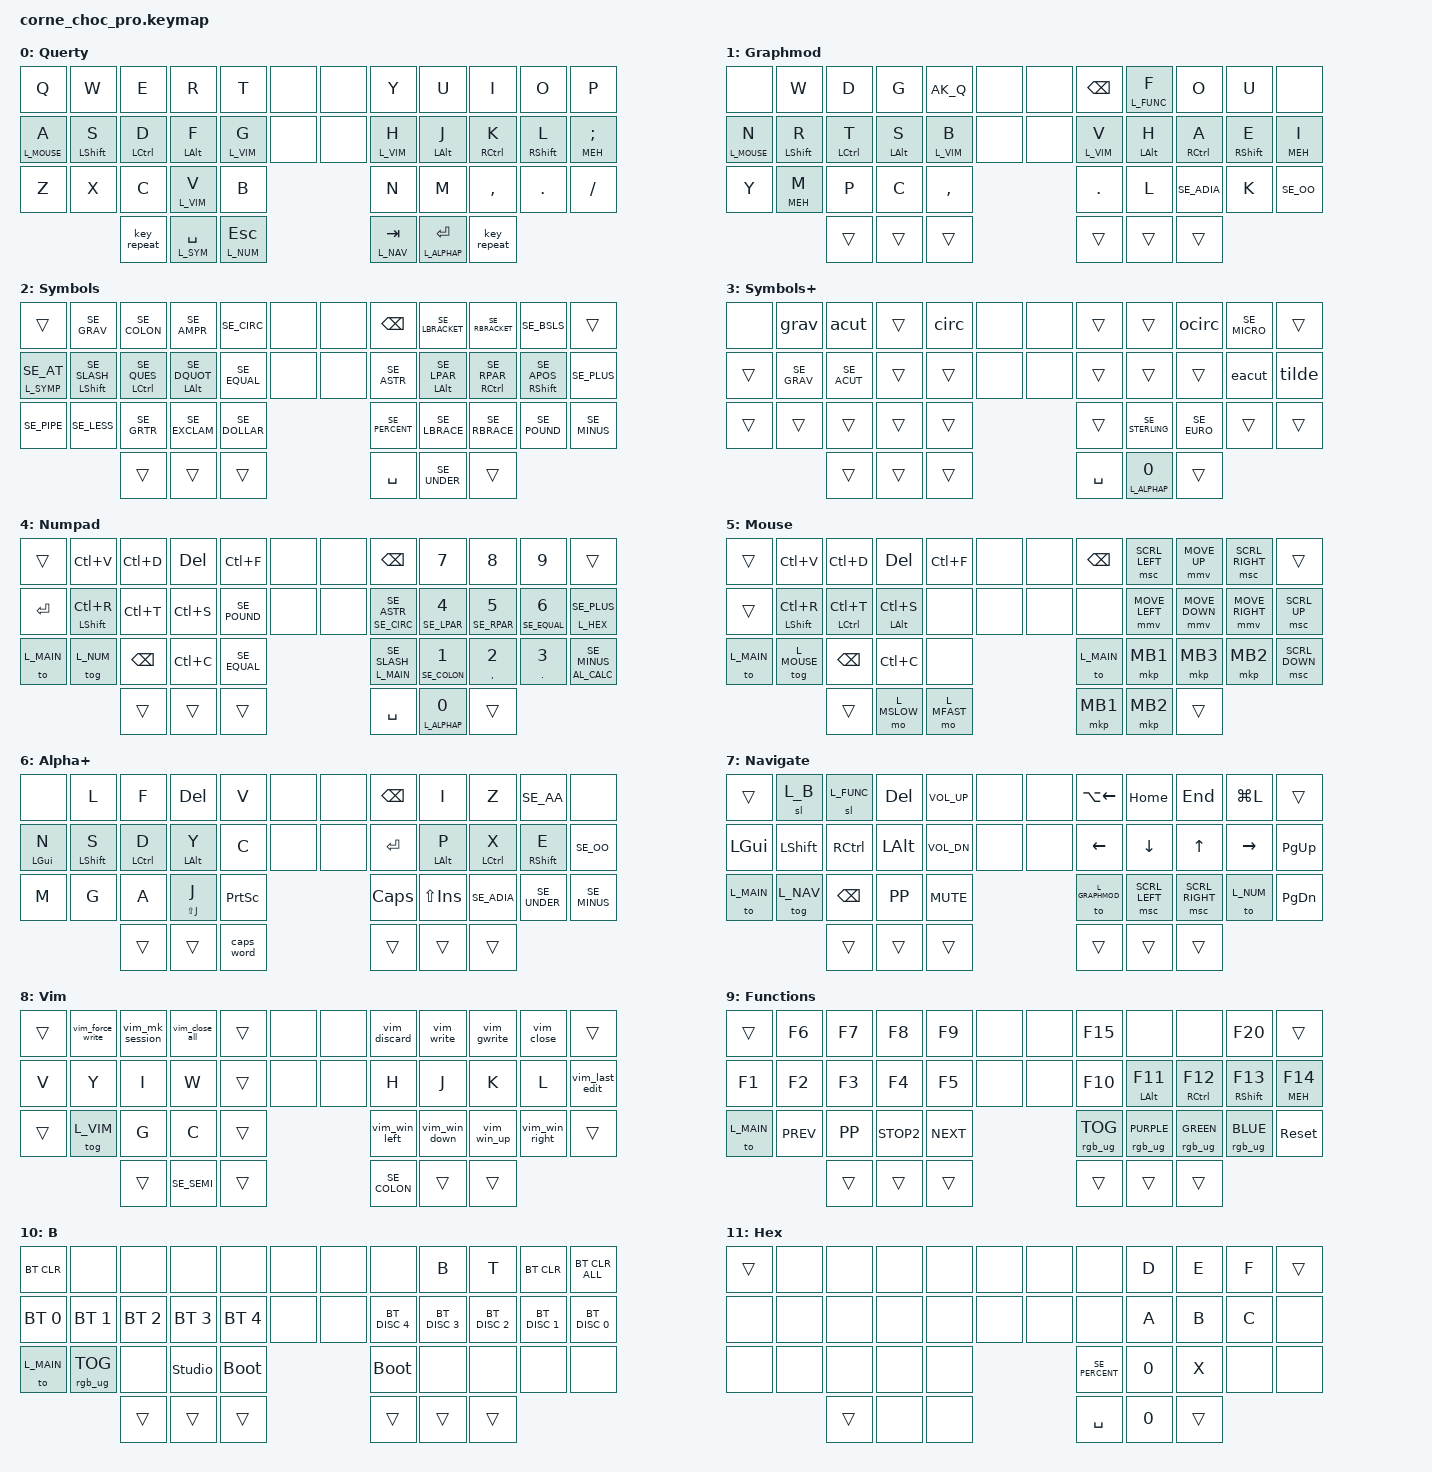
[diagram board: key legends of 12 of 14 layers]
/*
 * Copyright (c) 2020 The ZMK Contributors
 *
 * SPDX-License-Identifier: MIT
 */

#include <behaviors.dtsi>
#include <dt-bindings/zmk/keys.h>
#include <dt-bindings/zmk/bt.h>
#include <dt-bindings/zmk/rgb.h>
#include <dt-bindings/zmk/pointing.h>
#include <input/processors.dtsi>

#define SE_CIRC LS(RIGHT_BRACKET)
#define SE_DOLLAR RA(N4)
#define SE_COLON LS(DOT)
#define SE_SEMI LS(COMMA)
#define SE_AMPR LS(N6)
#define SE_ACUT EQUAL
#define SE_AT RA(N2)
#define SE_SLASH LS(N7)
#define SE_QUES LS(MINUS)
#define SE_DQUOT LS(N2)
#define SE_APOS NUHS
#define SE_LESS NUBS
#define SE_MINUS FSLH
#define SE_UNDER LS(FSLH)
#define SE_EQUAL LS(N0)
#define SE_GRTR LS(NUBS)
#define SE_LBRACE RA(N7)
#define SE_RBRACE RA(N0)
#define SE_BSLS RA(MINUS)
#define SE_TILDE RA(RIGHT_BRACKET)
#define SE_LPAR LS(N8)
#define SE_RPAR LS(N9)
#define SE_PLUS MINUS
#define SE_ASTR LS(NUHS)
#define SE_GRAV LS(EQUAL)
#define SE_LBRACKET RA(N8)
#define SE_RBRACKET RA(N9)
#define SE_PIPE RA(NUBS)
#define SE_SECT GRAV
#define SE_PERCENT LS(N5)
#define SE_EXCLAM LS(N1)
#define SE_POUND LS(N3)
#define SE_MICRO RA(M)
#define SE_EURO RA(N5)
#define SE_STERLING RA(N3)
#define SE_ADIA APOS
#define SE_AA LEFT_BRACKET
#define SE_OO SEMI

#define L_QWERTY 0
#define L_GRAPHMOD 1
#define L_SYM 2
#define L_SYMP 3
#define L_NUM 4
#define L_MOUSE 5
#define L_ALPHAP 6
#define L_NAV 7
#define L_VIM 8
#define L_FUNC 9
#define L_B 10
#define L_HEX 11
// Speed modifiers for the Mouse layer: all-&trans layers that exist only so the
// pointer/scroll input listeners can scale their events while one is held.
#define L_MFAST 12
#define L_MSLOW 13
#define L_MAIN L_QWERTY

// MEH = Ctrl + Shift + Alt
#define MEH LC(LS(LALT))

// Shortcuts for workspaces
#define WS_L LC(LA(LEFT))
#define WS_R LC(LA(RIGHT))
#define WSM_L LS(LA(LEFT))
#define WSM_R LS(LA(RIGHT))

// Colors
#define GREEN RGB_COLOR_HSB(128,100,100)
#define BLUE RGB_COLOR_HSB(225,85,95)
#define PURPLE RGB_COLOR_HSB(255,80,100)

/ {
    chosen {
        zmk,physical-layout = &five_col_layout;
    };
};

/ {
    behaviors {
        HML: HML {
            compatible = "zmk,behavior-hold-tap";
            bindings = <&kp>, <&kp>;

            #binding-cells = <2>;
            tapping-term-ms = <250>;
            quick-tap-ms = <175>;
            flavor = "balanced";
            hold-trigger-on-release;
            require-prior-idle-ms = <100>;
            hold-trigger-key-positions = <7 8 9 10 11 19 20 21 22 23 29 30 31 32 33>;
        };

        HMR: HMR {
            compatible = "zmk,behavior-hold-tap";
            bindings = <&kp>, <&kp>;

            #binding-cells = <2>;
            tapping-term-ms = <250>;
            quick-tap-ms = <175>;
            flavor = "balanced";
            hold-trigger-on-release;
            require-prior-idle-ms = <100>;
            hold-trigger-key-positions = <0 1 2 3 4 12 13 14 15 16 24 25 26 27 28>;
        };

        HT_TO: HT_TO {
            compatible = "zmk,behavior-hold-tap";
            bindings = <&to>, <&kp>;

            #binding-cells = <2>;
            tapping-term-ms = <250>;
            flavor = "tap-preferred";
        };

        NUM: NUM {
            compatible = "zmk,behavior-hold-tap";
            bindings = <&kp>, <&kp>;

            #binding-cells = <2>;
            tapping-term-ms = <200>;
            quick-tap-ms = <175>;
            require-prior-idle-ms = <100>;
            flavor = "tap-preferred";
        };

        LT_TH: LT_TH {
            compatible = "zmk,behavior-hold-tap";
            bindings = <&mo>, <&kp>;

            #binding-cells = <2>;
            tapping-term-ms = <200>;
            quick-tap-ms = <150>;
            require-prior-idle-ms = <100>;
            flavor = "tap-preferred";
        };

        // Adaptive Q: N -> Q sends J, otherwise plain Q.
        AK_Q: AK_Q {
            compatible = "zmk,behavior-adaptive-key";
            #binding-cells = <0>;
            bindings = <&kp Q>;

            ak_nq { trigger-keys = <N>; max-prior-idle-ms = <300>; bindings = <&kp J>; };
        };
    };
};

        //                               Key positions
        //
        //╭────┬────┬────┬────┬────╮                      ╭────┬────┬────┬────┬────╮
        //   0    1    2    3    4          5     6          7    8    9   10   11
        //├────┼────┼────┼────┼────┤                      ├────┼────┼────┼────┼────┤
        //  12   13   14   15   16         17    18         19   20   21   22   23
        //├────┼────┼────┼────┼────┤                      ├────┼────┼────┼────┼────┤
        //  24   25   26   27   28                          29   30   31   32   33
        //╰────┴────┼────┼────┼────┤                      ├────┼────┼────┼────┴────╯
        //            34   35   36                          37   38   39
        //          ╰────┴────┴────╯                      ╰────┴────┴────╯
        //
        // The layers are a port of the Kibård keymap (5x3 + 2 thumbs per half):
        // 5, 6, 17 and 18 are unused, and the outer thumbs 34/39 are repeat.


// Mouse speed control. `&mmv`/`&msc` feed their events through these listeners,
// so scaling them here changes pointer/scroll speed without touching a single
// binding: on the Mouse layer hold pos 36 (left inner thumb) for L_MFAST or
// pos 35 (left middle thumb) for L_MSLOW while the right hand drives the mouse.
// Both are `&trans` layers, so the Mouse layer keeps working underneath.
//
// The parameters are <multiplier divisor>, max 16 each. Tune here only.
&mmv_input_listener {
    fast { layers = <L_MFAST>; input-processors = <&zip_xy_scaler 3 1>; };
    slow { layers = <L_MSLOW>; input-processors = <&zip_xy_scaler 1 4>; };
};

&msc_input_listener {
    fast { layers = <L_MFAST>; input-processors = <&zip_scroll_scaler 2 1>; };
    slow { layers = <L_MSLOW>; input-processors = <&zip_scroll_scaler 1 3>; };
};

// Functions is a sticky layer (&sl from Navigate): it stays on until the next
// key press, or until this timeout passes with nothing pressed.
&sl {
    release-after-ms = <5000>;
};

/ {
    macros {
        vim_write: vim_write {
            compatible = "zmk,behavior-macro";
            #binding-cells = <0>;
            bindings
                = <&macro_press &kp LSHFT>
                , <&macro_tap &kp DOT>
                , <&macro_release &kp LSHFT>
                , <&macro_tap &kp W>
                , <&macro_tap &kp RET>
                ;
        };

        vim_close: vim_close {
            compatible = "zmk,behavior-macro";
            #binding-cells = <0>;
            bindings
                = <&macro_press &kp LSHFT>
                , <&macro_tap &kp DOT>
                , <&macro_release &kp LSHFT>
                , <&macro_tap &kp Q>
                , <&macro_tap &kp RET>
                ;
        };

        vim_close_all: vim_close_all {
            compatible = "zmk,behavior-macro";
            #binding-cells = <0>;
            bindings
                = <&macro_press &kp LSHFT>
                , <&macro_tap &kp DOT>
                , <&macro_release &kp LSHFT>
                , <&macro_tap &kp Q &kp A>
                , <&macro_tap &kp RET>
                ;
        };

        vim_mk_session: vim_mk_session {
            compatible = "zmk,behavior-macro";
            #binding-cells = <0>;
            bindings
                = <&macro_press &kp LSHFT>
                , <&macro_tap &kp DOT>
                , <&macro_release &kp LSHFT>
                , <&macro_tap &kp M &kp K &kp S &kp E &kp S &kp S &kp I &kp O &kp N>
                , <&macro_press &kp LSHFT>
                , <&macro_tap &kp N1>
                , <&macro_release &kp LSHFT>
                , <&macro_tap &kp RET>
                ;
        };

        vim_gwrite: vim_gwrite {
            compatible = "zmk,behavior-macro";
            #binding-cells = <0>;
            bindings
                = <&macro_press &kp LSHFT>
                , <&macro_tap &kp DOT>
                , <&macro_tap &kp G>
                , <&macro_release &kp LSHFT>
                , <&macro_tap &kp W &kp R &kp I &kp T &kp E>
                , <&macro_tap &kp RET>
                ;
        };

        vim_discard: vim_discard {
            compatible = "zmk,behavior-macro";
            #binding-cells = <0>;
            bindings
                = <&macro_press &kp LSHFT>
                , <&macro_tap &kp DOT>
                , <&macro_release &kp LSHFT>
                , <&macro_tap &kp Q>
                , <&macro_tap &kp SE_EXCLAM>
                , <&macro_tap &kp RET>
                ;
        };

        vim_force_write: vim_force_write {
            compatible = "zmk,behavior-macro";
            #binding-cells = <0>;
            bindings
                = <&macro_press &kp LSHFT>
                , <&macro_tap &kp DOT>
                , <&macro_release &kp LSHFT>
                , <&macro_tap &kp W>
                , <&macro_tap &kp SE_EXCLAM>
                , <&macro_tap &kp RET>
                ;
        };

        vim_win_left: vim_win_left {
            compatible = "zmk,behavior-macro";
            #binding-cells = <0>;
            bindings
                = <&macro_press &kp LCTRL>
                , <&macro_tap &kp W>
                , <&macro_release &kp LCTRL>
                , <&macro_tap &kp H>
                ;
        };

        vim_win_down: vim_win_down {
            compatible = "zmk,behavior-macro";
            #binding-cells = <0>;
            bindings
                = <&macro_press &kp LCTRL>
                , <&macro_tap &kp W>
                , <&macro_release &kp LCTRL>
                , <&macro_tap &kp J>
                ;
        };

        vim_win_up: vim_win_up {
            compatible = "zmk,behavior-macro";
            #binding-cells = <0>;
            bindings
                = <&macro_press &kp LCTRL>
                , <&macro_tap &kp W>
                , <&macro_release &kp LCTRL>
                , <&macro_tap &kp K>
                ;
        };

        vim_win_right: vim_win_right {
            compatible = "zmk,behavior-macro";
            #binding-cells = <0>;
            bindings
                = <&macro_press &kp LCTRL>
                , <&macro_tap &kp W>
                , <&macro_release &kp LCTRL>
                , <&macro_tap &kp L>
                ;
        };

        vim_last_edit: vim_last_edit {
            compatible = "zmk,behavior-macro";
            #binding-cells = <0>;
            bindings
                = <&macro_tap &kp G>
                , <&macro_press &kp LSHIFT>
                , <&macro_tap &kp COMMA>
                , <&macro_release &kp LSHIFT>
                ;
        };

        acut: acut {
            compatible = "zmk,behavior-macro";
            #binding-cells = <0>;
            bindings
                = <&macro_tap &kp SE_ACUT>
                , <&macro_tap &kp SE_ACUT>
                ;
        };

        grav: grav {
            compatible = "zmk,behavior-macro";
            #binding-cells = <0>;
            bindings
                = <&macro_tap &kp SE_GRAV>
                , <&macro_tap &kp SPACE>
                ;
        };

        tilde: tilde {
            compatible = "zmk,behavior-macro";
            #binding-cells = <0>;
            bindings
                = <&macro_tap &kp SE_TILDE>
                , <&macro_tap &kp SPACE>
                ;
        };

        circ: circ {
            compatible = "zmk,behavior-macro";
            #binding-cells = <0>;
            bindings
                = <&macro_tap &kp SE_CIRC>
                , <&macro_tap &kp SPACE>
                ;
        };

        eacut: eacut {
            compatible = "zmk,behavior-macro";
            #binding-cells = <0>;
            bindings
                = <&macro_tap &kp SE_ACUT>
                , <&macro_tap &kp E>
                ;
        };

        ocirc: ocirc {
            compatible = "zmk,behavior-macro";
            #binding-cells = <0>;
            bindings
                = <&macro_tap &kp SE_CIRC>
                , <&macro_tap &kp O>
                ;
        };
    };
};

/ {
    combos {
        compatible = "zmk,combos";

        combo_esc {
            timeout-ms = <40>;
            key-positions = <1 2>;
            bindings = <&kp ESC>;
        };
    };
};

/ {
    keymap {
        compatible = "zmk,keymap";

        default_layer {
            display-name = "Querty";
            bindings = <
                //╭─────────────────┬─────────────────┬─────────────────┬─────────────────┬─────────────────╮                      ╭─────────────────┬─────────────────┬─────────────────┬─────────────────┬─────────────────╮
                    &kp Q             &kp W             &kp E             &kp R             &kp T                 &none  &none       &kp Y             &kp U             &kp I             &kp O             &kp P
                //├─────────────────┼─────────────────┼─────────────────┼─────────────────┼─────────────────┤                      ├─────────────────┼─────────────────┼─────────────────┼─────────────────┼─────────────────┤
                    &LT_TH L_MOUSE A  &HML LSHIFT S     &HML LCTRL D      &HML LALT F       &lt L_VIM G           &none  &none       &lt L_VIM H       &HMR LALT J       &HMR RCTRL K      &HMR RSHIFT L     &HMR MEH SEMI
                //├─────────────────┼─────────────────┼─────────────────┼─────────────────┼─────────────────┤                      ├─────────────────┼─────────────────┼─────────────────┼─────────────────┼─────────────────┤
                    &kp Z             &kp X             &kp C             &lt L_VIM V       &kp B                                    &kp N             &kp M             &kp COMMA         &kp DOT           &kp FSLH
                //╰─────────────────┴─────────────────┼─────────────────┼─────────────────┼─────────────────┤                      ├─────────────────┼─────────────────┼─────────────────┼─────────────────┴─────────────────╯
                                                        &key_repeat       &LT_TH L_SYM SPACE  &LT_TH L_NUM ESC                       &LT_TH L_NAV TAB  &LT_TH L_ALPHAP RET  &key_repeat
                //                                    ╰─────────────────┴─────────────────┴─────────────────╯                      ╰─────────────────┴─────────────────┴─────────────────╯
            >;
        };

        graphmod_layer {
            display-name = "Graphmod";
            bindings = <
                //╭─────────────────┬─────────────────┬─────────────────┬─────────────────┬─────────────────╮                      ╭─────────────────┬─────────────────┬─────────────────┬─────────────────┬─────────────────╮
                    &none             &kp W             &kp D             &kp G             &AK_Q                 &none  &none       &kp BSPC          &lt L_FUNC F      &kp O             &kp U             &none
                //├─────────────────┼─────────────────┼─────────────────┼─────────────────┼─────────────────┤                      ├─────────────────┼─────────────────┼─────────────────┼─────────────────┼─────────────────┤
                    &LT_TH L_MOUSE N  &HML LSHIFT R     &HML LCTRL T      &HML LALT S       &lt L_VIM B           &none  &none       &lt L_VIM V       &HMR LALT H       &HMR RCTRL A      &HMR RSHIFT E     &HMR MEH I
                //├─────────────────┼─────────────────┼─────────────────┼─────────────────┼─────────────────┤                      ├─────────────────┼─────────────────┼─────────────────┼─────────────────┼─────────────────┤
                    &kp Y             &HML MEH M        &kp P             &kp C             &kp COMMA                                &kp DOT           &kp L             &kp SE_ADIA       &kp K             &kp SE_OO
                //╰─────────────────┴─────────────────┼─────────────────┼─────────────────┼─────────────────┤                      ├─────────────────┼─────────────────┼─────────────────┼─────────────────┴─────────────────╯
                                                        &trans            &trans            &trans                                   &trans            &trans            &trans
                //                                    ╰─────────────────┴─────────────────┴─────────────────╯                      ╰─────────────────┴─────────────────┴─────────────────╯
            >;
        };

        symbol_layer {
            display-name = "Symbols";
            bindings = <
                //╭─────────────────┬─────────────────┬─────────────────┬─────────────────┬─────────────────╮                      ╭─────────────────┬─────────────────┬─────────────────┬─────────────────┬─────────────────╮
                    &trans            &kp SE_GRAV       &kp SE_COLON      &kp SE_AMPR       &kp SE_CIRC           &none  &none       &kp BSPC          &kp SE_LBRACKET   &kp SE_RBRACKET   &kp SE_BSLS       &trans
                //├─────────────────┼─────────────────┼─────────────────┼─────────────────┼─────────────────┤                      ├─────────────────┼─────────────────┼─────────────────┼─────────────────┼─────────────────┤
                    &LT_TH L_SYMP SE_AT  &HML LSHIFT SE_SLASH  &HML LCTRL SE_QUES  &HML LALT SE_DQUOT  &kp SE_EQUAL  &none  &none    &kp SE_ASTR       &HMR LALT SE_LPAR  &HMR RCTRL SE_RPAR  &HMR RSHIFT SE_APOS  &kp SE_PLUS
                //├─────────────────┼─────────────────┼─────────────────┼─────────────────┼─────────────────┤                      ├─────────────────┼─────────────────┼─────────────────┼─────────────────┼─────────────────┤
                    &kp SE_PIPE       &kp SE_LESS       &kp SE_GRTR       &kp SE_EXCLAM     &kp SE_DOLLAR                            &kp SE_PERCENT    &kp SE_LBRACE     &kp SE_RBRACE     &kp SE_POUND      &kp SE_MINUS
                //╰─────────────────┴─────────────────┼─────────────────┼─────────────────┼─────────────────┤                      ├─────────────────┼─────────────────┼─────────────────┼─────────────────┴─────────────────╯
                                                        &trans            &trans            &trans                                   &kp SPACE         &kp SE_UNDER      &trans
                //                                    ╰─────────────────┴─────────────────┴─────────────────╯                      ╰─────────────────┴─────────────────┴─────────────────╯
            >;
        };

        symbolplus_layer {
            display-name = "Symbols+";
            bindings = <
                //╭─────────────────┬─────────────────┬─────────────────┬─────────────────┬─────────────────╮                      ╭─────────────────┬─────────────────┬─────────────────┬─────────────────┬─────────────────╮
                    &none             &grav             &acut             &trans            &circ                 &none  &none       &trans            &trans            &ocirc            &kp SE_MICRO      &trans
                //├─────────────────┼─────────────────┼─────────────────┼─────────────────┼─────────────────┤                      ├─────────────────┼─────────────────┼─────────────────┼─────────────────┼─────────────────┤
                    &trans            &kp SE_GRAV       &kp SE_ACUT       &trans            &trans                &none  &none       &trans            &trans            &trans            &eacut            &tilde
                //├─────────────────┼─────────────────┼─────────────────┼─────────────────┼─────────────────┤                      ├─────────────────┼─────────────────┼─────────────────┼─────────────────┼─────────────────┤
                    &trans            &trans            &trans            &trans            &trans                                   &trans            &kp SE_STERLING   &kp SE_EURO       &trans            &trans
                //╰─────────────────┴─────────────────┼─────────────────┼─────────────────┼─────────────────┤                      ├─────────────────┼─────────────────┼─────────────────┼─────────────────┴─────────────────╯
                                                        &trans            &trans            &trans                                   &kp SPACE         &lt L_ALPHAP N0   &trans
                //                                    ╰─────────────────┴─────────────────┴─────────────────╯                      ╰─────────────────┴─────────────────┴─────────────────╯
            >;
        };

        numpad_layer {
            display-name = "Numpad";
            bindings = <
                //╭─────────────────┬─────────────────┬─────────────────┬─────────────────┬─────────────────╮                      ╭─────────────────┬─────────────────┬─────────────────┬─────────────────┬─────────────────╮
                    &trans            &kp LC(V)         &kp LC(D)         &kp DEL           &kp LC(F)             &none  &none       &kp BSPC          &kp N7            &kp N8            &kp N9            &trans
                //├─────────────────┼─────────────────┼─────────────────┼─────────────────┼─────────────────┤                      ├─────────────────┼─────────────────┼─────────────────┼─────────────────┼─────────────────┤
                    &kp RET           &HML LSHIFT LC(R)  &kp LC(T)        &kp LC(S)         &kp SE_POUND          &none  &none       &NUM SE_CIRC SE_ASTR  &NUM SE_LPAR N4  &NUM SE_RPAR N5  &NUM SE_EQUAL N6  &LT_TH L_HEX SE_PLUS
                //├─────────────────┼─────────────────┼─────────────────┼─────────────────┼─────────────────┤                      ├─────────────────┼─────────────────┼─────────────────┼─────────────────┼─────────────────┤
                    &to L_MAIN        &tog L_NUM        &kp BSPC          &kp LC(C)         &kp SE_EQUAL                             &HT_TO L_MAIN SE_SLASH  &NUM SE_COLON N1  &NUM COMMA N2  &NUM DOT N3    &NUM C_AL_CALC SE_MINUS
                //╰─────────────────┴─────────────────┼─────────────────┼─────────────────┼─────────────────┤                      ├─────────────────┼─────────────────┼─────────────────┼─────────────────┴─────────────────╯
                                                        &trans            &trans            &trans                                   &kp SPACE         &lt L_ALPHAP N0   &trans
                //                                    ╰─────────────────┴─────────────────┴─────────────────╯                      ╰─────────────────┴─────────────────┴─────────────────╯
            >;
        };

        mouse_layer {
            display-name = "Mouse";
            bindings = <
                //╭─────────────────┬─────────────────┬─────────────────┬─────────────────┬─────────────────╮                      ╭─────────────────┬─────────────────┬─────────────────┬─────────────────┬─────────────────╮
                    &trans            &kp LC(V)         &kp LC(D)         &kp DEL           &kp LC(F)             &none  &none       &kp BSPC          &msc SCRL_LEFT    &mmv MOVE_UP      &msc SCRL_RIGHT   &trans
                //├─────────────────┼─────────────────┼─────────────────┼─────────────────┼─────────────────┤                      ├─────────────────┼─────────────────┼─────────────────┼─────────────────┼─────────────────┤
                    &trans            &HML LSHIFT LC(R)  &HML LCTRL LC(T)  &HML LALT LC(S)  &none                 &none  &none       &none             &mmv MOVE_LEFT    &mmv MOVE_DOWN    &mmv MOVE_RIGHT   &msc SCRL_UP
                //├─────────────────┼─────────────────┼─────────────────┼─────────────────┼─────────────────┤                      ├─────────────────┼─────────────────┼─────────────────┼─────────────────┼─────────────────┤
                    &to L_MAIN        &tog L_MOUSE      &kp BSPC          &kp LC(C)         &none                                    &to L_MAIN        &mkp MB1          &mkp MB3          &mkp MB2          &msc SCRL_DOWN
                //╰─────────────────┴─────────────────┼─────────────────┼─────────────────┼─────────────────┤                      ├─────────────────┼─────────────────┼─────────────────┼─────────────────┴─────────────────╯
                                                        &trans            &mo L_MSLOW       &mo L_MFAST                              &mkp MB1          &mkp MB2          &trans
                //                                    ╰─────────────────┴─────────────────┴─────────────────╯                      ╰─────────────────┴─────────────────┴─────────────────╯
            >;
        };

        alphaplus_layer {
            display-name = "Alpha+";
            bindings = <
                //╭─────────────────┬─────────────────┬─────────────────┬─────────────────┬─────────────────╮                      ╭─────────────────┬─────────────────┬─────────────────┬─────────────────┬─────────────────╮
                    &none             &kp L             &kp F             &kp DEL           &kp V                 &none  &none       &kp BSPC          &kp I             &kp Z             &kp SE_AA         &none
                //├─────────────────┼─────────────────┼─────────────────┼─────────────────┼─────────────────┤                      ├─────────────────┼─────────────────┼─────────────────┼─────────────────┼─────────────────┤
                    &HML LGUI N       &HML LSHIFT S     &HML LCTRL D      &HML LALT Y       &kp C                 &none  &none       &kp RET           &HMR LALT P       &HMR LCTRL X      &HMR RSHIFT E     &kp SE_OO
                //├─────────────────┼─────────────────┼─────────────────┼─────────────────┼─────────────────┤                      ├─────────────────┼─────────────────┼─────────────────┼─────────────────┼─────────────────┤
                    &kp M             &kp G             &kp A             &HML LS(J) J      &kp PSCRN                                &kp CAPS          &kp LS(INS)       &kp SE_ADIA       &kp SE_UNDER      &kp SE_MINUS
                //╰─────────────────┴─────────────────┼─────────────────┼─────────────────┼─────────────────┤                      ├─────────────────┼─────────────────┼─────────────────┼─────────────────┴─────────────────╯
                                                        &trans            &trans            &caps_word                               &trans            &trans            &trans
                //                                    ╰─────────────────┴─────────────────┴─────────────────╯                      ╰─────────────────┴─────────────────┴─────────────────╯
            >;
        };

        navigate_layer {
            display-name = "Navigate";
            bindings = <
                //╭─────────────────┬─────────────────┬─────────────────┬─────────────────┬─────────────────╮                      ╭─────────────────┬─────────────────┬─────────────────┬─────────────────┬─────────────────╮
                    &trans            &sl L_B           &sl L_FUNC        &kp DEL           &kp K_VOL_UP          &none  &none       &kp LA(LEFT)      &kp HOME          &kp END           &kp LG(L)         &trans
                //├─────────────────┼─────────────────┼─────────────────┼─────────────────┼─────────────────┤                      ├─────────────────┼─────────────────┼─────────────────┼─────────────────┼─────────────────┤
                    &kp LGUI          &kp LSHIFT        &kp RCTRL         &kp LALT          &kp K_VOL_DN          &none  &none       &kp LEFT          &kp DOWN          &kp UP            &kp RIGHT         &kp PG_UP
                //├─────────────────┼─────────────────┼─────────────────┼─────────────────┼─────────────────┤                      ├─────────────────┼─────────────────┼─────────────────┼─────────────────┼─────────────────┤
                    &to L_MAIN        &tog L_NAV        &kp BSPC          &kp K_PP          &kp K_MUTE                               &to L_GRAPHMOD    &msc SCRL_LEFT    &msc SCRL_RIGHT   &to L_NUM         &kp PG_DN
                //╰─────────────────┴─────────────────┼─────────────────┼─────────────────┼─────────────────┤                      ├─────────────────┼─────────────────┼─────────────────┼─────────────────┴─────────────────╯
                                                        &trans            &trans            &trans                                   &trans            &trans            &trans
                //                                    ╰─────────────────┴─────────────────┴─────────────────╯                      ╰─────────────────┴─────────────────┴─────────────────╯
            >;
        };

        vim_layer {
            display-name = "Vim";
            bindings = <
                //╭─────────────────┬─────────────────┬─────────────────┬─────────────────┬─────────────────╮                      ╭─────────────────┬─────────────────┬─────────────────┬─────────────────┬─────────────────╮
                    &trans            &vim_force_write  &vim_mk_session   &vim_close_all    &trans                &none  &none       &vim_discard      &vim_write        &vim_gwrite       &vim_close        &trans
                //├─────────────────┼─────────────────┼─────────────────┼─────────────────┼─────────────────┤                      ├─────────────────┼─────────────────┼─────────────────┼─────────────────┼─────────────────┤
                    &kp V             &kp Y             &kp I             &kp W             &trans                &none  &none       &kp H             &kp J             &kp K             &kp L             &vim_last_edit
                //├─────────────────┼─────────────────┼─────────────────┼─────────────────┼─────────────────┤                      ├─────────────────┼─────────────────┼─────────────────┼─────────────────┼─────────────────┤
                    &trans            &tog L_VIM        &kp G             &kp C             &trans                                   &vim_win_left     &vim_win_down     &vim_win_up       &vim_win_right    &trans
                //╰─────────────────┴─────────────────┼─────────────────┼─────────────────┼─────────────────┤                      ├─────────────────┼─────────────────┼─────────────────┼─────────────────┴─────────────────╯
                                                        &trans            &kp SE_SEMI       &trans                                   &kp SE_COLON      &trans            &trans
                //                                    ╰─────────────────┴─────────────────┴─────────────────╯                      ╰─────────────────┴─────────────────┴─────────────────╯
            >;
        };

        functions_layer {
            display-name = "Functions";
            bindings = <
                //╭─────────────────┬─────────────────┬─────────────────┬─────────────────┬─────────────────╮                      ╭─────────────────┬─────────────────┬─────────────────┬─────────────────┬─────────────────╮
                    &trans            &kp F6            &kp F7            &kp F8            &kp F9                &none  &none       &kp F15           &none             &none             &kp F20           &trans
                //├─────────────────┼─────────────────┼─────────────────┼─────────────────┼─────────────────┤                      ├─────────────────┼─────────────────┼─────────────────┼─────────────────┼─────────────────┤
                    &kp F1            &kp F2            &kp F3            &kp F4            &kp F5                &none  &none       &kp F10           &HMR LALT F11     &HMR RCTRL F12    &HMR RSHIFT F13   &HMR MEH F14
                //├─────────────────┼─────────────────┼─────────────────┼─────────────────┼─────────────────┤                      ├─────────────────┼─────────────────┼─────────────────┼─────────────────┼─────────────────┤
                    &to L_MAIN        &kp K_PREV        &kp K_PP          &kp K_STOP2       &kp K_NEXT                               &rgb_ug RGB_TOG   &rgb_ug PURPLE    &rgb_ug GREEN     &rgb_ug BLUE      &sys_reset
                //╰─────────────────┴─────────────────┼─────────────────┼─────────────────┼─────────────────┤                      ├─────────────────┼─────────────────┼─────────────────┼─────────────────┴─────────────────╯
                                                        &trans            &trans            &trans                                   &trans            &trans            &trans
                //                                    ╰─────────────────┴─────────────────┴─────────────────╯                      ╰─────────────────┴─────────────────┴─────────────────╯
            >;
        };

        b_layer {
            display-name = "B";
            bindings = <
                //╭─────────────────┬─────────────────┬─────────────────┬─────────────────┬─────────────────╮                      ╭─────────────────┬─────────────────┬─────────────────┬─────────────────┬─────────────────╮
                    &bt BT_CLR        &none             &none             &none             &none                 &none  &none       &none             &kp B             &kp T             &bt BT_CLR        &bt BT_CLR_ALL
                //├─────────────────┼─────────────────┼─────────────────┼─────────────────┼─────────────────┤                      ├─────────────────┼─────────────────┼─────────────────┼─────────────────┼─────────────────┤
                    &bt BT_SEL 0      &bt BT_SEL 1      &bt BT_SEL 2      &bt BT_SEL 3      &bt BT_SEL 4          &none  &none       &bt BT_DISC 4     &bt BT_DISC 3     &bt BT_DISC 2     &bt BT_DISC 1     &bt BT_DISC 0
                //├─────────────────┼─────────────────┼─────────────────┼─────────────────┼─────────────────┤                      ├─────────────────┼─────────────────┼─────────────────┼─────────────────┼─────────────────┤
                    &to L_MAIN        &rgb_ug RGB_TOG   &none             &studio_unlock    &bootloader                              &bootloader       &none             &none             &none             &none
                //╰─────────────────┴─────────────────┼─────────────────┼─────────────────┼─────────────────┤                      ├─────────────────┼─────────────────┼─────────────────┼─────────────────┴─────────────────╯
                                                        &trans            &trans            &trans                                   &trans            &trans            &trans
                //                                    ╰─────────────────┴─────────────────┴─────────────────╯                      ╰─────────────────┴─────────────────┴─────────────────╯
            >;
        };

        hex_layer {
            display-name = "Hex";
            bindings = <
                //╭─────────────────┬─────────────────┬─────────────────┬─────────────────┬─────────────────╮                      ╭─────────────────┬─────────────────┬─────────────────┬─────────────────┬─────────────────╮
                    &trans            &none             &none             &none             &none                 &none  &none       &none             &kp D             &kp E             &kp F             &trans
                //├─────────────────┼─────────────────┼─────────────────┼─────────────────┼─────────────────┤                      ├─────────────────┼─────────────────┼─────────────────┼─────────────────┼─────────────────┤
                    &none             &none             &none             &none             &none                 &none  &none       &none             &kp A             &kp B             &kp C             &none
                //├─────────────────┼─────────────────┼─────────────────┼─────────────────┼─────────────────┤                      ├─────────────────┼─────────────────┼─────────────────┼─────────────────┼─────────────────┤
                    &none             &none             &none             &none             &none                                    &kp SE_PERCENT    &kp N0            &kp X             &none             &none
                //╰─────────────────┴─────────────────┼─────────────────┼─────────────────┼─────────────────┤                      ├─────────────────┼─────────────────┼─────────────────┼─────────────────┴─────────────────╯
                                                        &trans            &none             &none                                    &kp SPACE         &kp N0            &trans
                //                                    ╰─────────────────┴─────────────────┴─────────────────╯                      ╰─────────────────┴─────────────────┴─────────────────╯
            >;
        };

        mouse_fast_layer {
            display-name = "Mouse fast";
            // Empty by design: held from the Mouse layer, it only tells &mmv_input_listener/&msc_input_listener to scale up.
            bindings = <
                //╭─────────────────┬─────────────────┬─────────────────┬─────────────────┬─────────────────╮                      ╭─────────────────┬─────────────────┬─────────────────┬─────────────────┬─────────────────╮
                    &trans            &trans            &trans            &trans            &trans                &none  &none       &trans            &trans            &trans            &trans            &trans
                //├─────────────────┼─────────────────┼─────────────────┼─────────────────┼─────────────────┤                      ├─────────────────┼─────────────────┼─────────────────┼─────────────────┼─────────────────┤
                    &trans            &trans            &trans            &trans            &trans                &none  &none       &trans            &trans            &trans            &trans            &trans
                //├─────────────────┼─────────────────┼─────────────────┼─────────────────┼─────────────────┤                      ├─────────────────┼─────────────────┼─────────────────┼─────────────────┼─────────────────┤
                    &trans            &trans            &trans            &trans            &trans                                   &trans            &trans            &trans            &trans            &trans
                //╰─────────────────┴─────────────────┼─────────────────┼─────────────────┼─────────────────┤                      ├─────────────────┼─────────────────┼─────────────────┼─────────────────┴─────────────────╯
                                                        &trans            &trans            &trans                                   &trans            &trans            &trans
                //                                    ╰─────────────────┴─────────────────┴─────────────────╯                      ╰─────────────────┴─────────────────┴─────────────────╯
            >;
        };

        mouse_slow_layer {
            display-name = "Mouse slow";
            // Empty by design: the L_MFAST twin, scaling movement down for precision aiming.
            bindings = <
                //╭─────────────────┬─────────────────┬─────────────────┬─────────────────┬─────────────────╮                      ╭─────────────────┬─────────────────┬─────────────────┬─────────────────┬─────────────────╮
                    &trans            &trans            &trans            &trans            &trans                &none  &none       &trans            &trans            &trans            &trans            &trans
                //├─────────────────┼─────────────────┼─────────────────┼─────────────────┼─────────────────┤                      ├─────────────────┼─────────────────┼─────────────────┼─────────────────┼─────────────────┤
                    &trans            &trans            &trans            &trans            &trans                &none  &none       &trans            &trans            &trans            &trans            &trans
                //├─────────────────┼─────────────────┼─────────────────┼─────────────────┼─────────────────┤                      ├─────────────────┼─────────────────┼─────────────────┼─────────────────┼─────────────────┤
                    &trans            &trans            &trans            &trans            &trans                                   &trans            &trans            &trans            &trans            &trans
                //╰─────────────────┴─────────────────┼─────────────────┼─────────────────┼─────────────────┤                      ├─────────────────┼─────────────────┼─────────────────┼─────────────────┴─────────────────╯
                                                        &trans            &trans            &trans                                   &trans            &trans            &trans
                //                                    ╰─────────────────┴─────────────────┴─────────────────╯                      ╰─────────────────┴─────────────────┴─────────────────╯
            >;
        };
    };
};



                //╭─────────────────┬─────────────────┬─────────────────┬─────────────────┬─────────────────╮                      ╭─────────────────┬─────────────────┬─────────────────┬─────────────────┬─────────────────╮
                //  &trans            &trans            &trans            &trans            &trans                &none  &none       &trans            &trans            &trans            &trans            &trans
                //├─────────────────┼─────────────────┼─────────────────┼─────────────────┼─────────────────┤                      ├─────────────────┼─────────────────┼─────────────────┼─────────────────┼─────────────────┤
                //  &trans            &trans            &trans            &trans            &trans                &none  &none       &trans            &trans            &trans            &trans            &trans
                //├─────────────────┼─────────────────┼─────────────────┼─────────────────┼─────────────────┤                      ├─────────────────┼─────────────────┼─────────────────┼─────────────────┼─────────────────┤
                //  &trans            &trans            &trans            &trans            &trans                                   &trans            &trans            &trans            &trans            &trans
                //╰─────────────────┴─────────────────┼─────────────────┼─────────────────┼─────────────────┤                      ├─────────────────┼─────────────────┼─────────────────┼─────────────────┴─────────────────╯
                //                                      &trans            &trans            &trans                                   &trans            &trans            &trans
                //                                    ╰─────────────────┴─────────────────┴─────────────────╯                      ╰─────────────────┴─────────────────┴─────────────────╯

